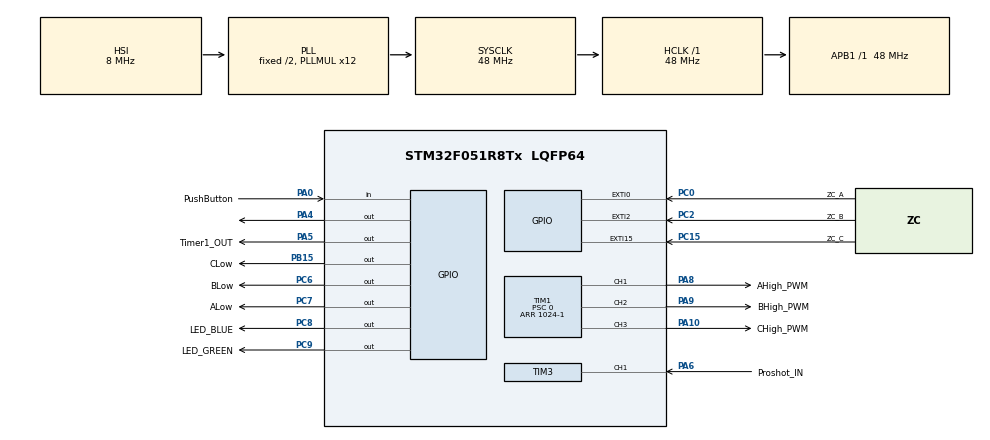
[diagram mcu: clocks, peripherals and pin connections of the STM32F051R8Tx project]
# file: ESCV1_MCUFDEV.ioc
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Dma.Request0=TIM3_CH1/TRIG
Dma.Request1=TIM1_CH2
Dma.Request2=TIM1_CH3/UP
Dma.Request3=TIM1_CH1
Dma.TIM1_CH1.3.Direction=DMA_MEMORY_TO_PERIPH
Dma.TIM1_CH1.3.Instance=DMA1_Channel2
Dma.TIM1_CH1.3.MemDataAlignment=DMA_MDATAALIGN_HALFWORD
Dma.TIM1_CH1.3.MemInc=DMA_MINC_ENABLE
Dma.TIM1_CH1.3.Mode=DMA_CIRCULAR
Dma.TIM1_CH1.3.PeriphDataAlignment=DMA_PDATAALIGN_HALFWORD
Dma.TIM1_CH1.3.PeriphInc=DMA_PINC_DISABLE
Dma.TIM1_CH1.3.Priority=DMA_PRIORITY_VERY_HIGH
Dma.TIM1_CH2.1.Direction=DMA_MEMORY_TO_PERIPH
Dma.TIM1_CH2.1.Instance=DMA1_Channel3
Dma.TIM1_CH2.1.MemDataAlignment=DMA_MDATAALIGN_HALFWORD
Dma.TIM1_CH2.1.MemInc=DMA_MINC_ENABLE
Dma.TIM1_CH2.1.Mode=DMA_CIRCULAR
Dma.TIM1_CH2.1.PeriphDataAlignment=DMA_PDATAALIGN_HALFWORD
Dma.TIM1_CH2.1.PeriphInc=DMA_PINC_DISABLE
Dma.TIM1_CH2.1.Priority=DMA_PRIORITY_VERY_HIGH
Dma.TIM1_CH3/UP.2.Direction=DMA_MEMORY_TO_PERIPH
Dma.TIM1_CH3/UP.2.Instance=DMA1_Channel5
Dma.TIM1_CH3/UP.2.MemDataAlignment=DMA_MDATAALIGN_HALFWORD
Dma.TIM1_CH3/UP.2.MemInc=DMA_MINC_ENABLE
Dma.TIM1_CH3/UP.2.Mode=DMA_CIRCULAR
Dma.TIM1_CH3/UP.2.PeriphDataAlignment=DMA_PDATAALIGN_HALFWORD
Dma.TIM1_CH3/UP.2.PeriphInc=DMA_PINC_DISABLE
Dma.TIM1_CH3/UP.2.Priority=DMA_PRIORITY_VERY_HIGH
Dma.TIM3_CH1/TRIG.0.Direction=DMA_PERIPH_TO_MEMORY
Dma.TIM3_CH1/TRIG.0.Instance=DMA1_Channel4
Dma.TIM3_CH1/TRIG.0.MemDataAlignment=DMA_MDATAALIGN_HALFWORD
Dma.TIM3_CH1/TRIG.0.MemInc=DMA_MINC_ENABLE
Dma.TIM3_CH1/TRIG.0.Mode=DMA_NORMAL
Dma.TIM3_CH1/TRIG.0.PeriphDataAlignment=DMA_PDATAALIGN_HALFWORD
Dma.TIM3_CH1/TRIG.0.PeriphInc=DMA_PINC_DISABLE
Dma.TIM3_CH1/TRIG.0.Priority=DMA_PRIORITY_VERY_HIGH
Mcu.Family=STM32F0
Mcu.Name=STM32F051R8Tx
Mcu.Package=LQFP64
NVIC.DMA1_Channel4_5_IRQn=true\:1\:0\:true\:false\:true\:true\:true
NVIC.EXTI0_1_IRQn=true\:0\:0\:false\:false\:true\:true\:true
NVIC.EXTI2_3_IRQn=true\:0\:0\:false\:false\:true\:true\:true
NVIC.EXTI4_15_IRQn=true\:0\:0\:false\:false\:true\:true\:true
NVIC.TIM2_IRQn=true\:0\:0\:true\:false\:true\:true\:true
PA0.GPIO_Label=PushButton
PA0.Signal=GPIO_Input
PA10.GPIO_Label=CHigh_PWM
PA10.GPIO_PuPd=GPIO_NOPULL
PA10.Signal=S_TIM1_CH3
PA13.Mode=Serial_Wire
PA13.Signal=SYS_SWDIO
PA14.Mode=Serial_Wire
PA14.Signal=SYS_SWCLK
PA4.Signal=GPIO_Output
PA5.GPIO_Label=Timer1_OUT
PA5.Signal=GPIO_Output
PA6.GPIO_Label=Proshot_IN
PA6.Signal=S_TIM3_CH1
PA8.GPIO_Label=AHigh_PWM
PA8.GPIO_PuPd=GPIO_NOPULL
PA8.Signal=S_TIM1_CH1
PA9.GPIO_Label=BHigh_PWM
PA9.GPIO_PuPd=GPIO_NOPULL
PA9.Signal=S_TIM1_CH2
PB15.GPIO_Label=CLow
PB15.GPIO_ModeDefaultOutputPP=GPIO_MODE_OUTPUT_PP
PB15.GPIO_PuPd=GPIO_PULLUP
PB15.GPIO_Speed=GPIO_SPEED_FREQ_HIGH
PB15.PinState=GPIO_PIN_SET
PB15.Signal=GPIO_Output
PC0.GPIO_Label=ZC_A
PC0.GPIO_ModeDefaultEXTI=GPIO_MODE_IT_FALLING
PC0.GPIO_PuPd=GPIO_PULLUP
PC0.Signal=GPXTI0
PC15-OSC32_OUT.GPIO_Label=ZC_C
PC15-OSC32_OUT.GPIO_ModeDefaultEXTI=GPIO_MODE_IT_FALLING
PC15-OSC32_OUT.GPIO_PuPd=GPIO_PULLUP
PC15-OSC32_OUT.Signal=GPXTI15
PC2.GPIO_Label=ZC_B
PC2.GPIO_ModeDefaultEXTI=GPIO_MODE_IT_FALLING
PC2.GPIO_PuPd=GPIO_PULLUP
PC2.Signal=GPXTI2
PC6.GPIO_Label=BLow
PC6.GPIO_ModeDefaultOutputPP=GPIO_MODE_OUTPUT_PP
PC6.GPIO_PuPd=GPIO_PULLUP
PC6.GPIO_Speed=GPIO_SPEED_FREQ_HIGH
PC6.PinState=GPIO_PIN_SET
PC6.Signal=GPIO_Output
PC7.GPIO_Label=ALow
PC7.GPIO_PuPd=GPIO_PULLUP
PC7.GPIO_Speed=GPIO_SPEED_FREQ_HIGH
PC7.PinState=GPIO_PIN_SET
PC7.Signal=GPIO_Output
PC8.GPIO_Label=LED_BLUE
PC8.Signal=GPIO_Output
PC9.GPIO_Label=LED_GREEN
PC9.GPIO_PuPd=GPIO_NOPULL
PC9.Signal=GPIO_Output
PF0-OSC_IN.Mode=HSE-External-Clock-Source
PF0-OSC_IN.Signal=RCC_OSC_IN
ProjectManager.HeapSize=0x200
ProjectManager.StackSize=0x400
ProjectManager.TargetToolchain=STM32CubeIDE
RCC.AHBFreq_Value=48000000
RCC.APB1Freq_Value=48000000
RCC.APB1TimFreq_Value=48000000
RCC.HCLKFreq_Value=48000000
RCC.PLLMUL=RCC_PLL_MUL12
RCC.SYSCLKFreq_VALUE=48000000
RCC.SYSCLKSource=RCC_SYSCLKSOURCE_PLLCLK
SH.S_TIM1_CH1.0=TIM1_CH1,PWM Generation1 CH1
SH.S_TIM1_CH2.0=TIM1_CH2,PWM Generation2 CH2
SH.S_TIM1_CH3.0=TIM1_CH3,PWM Generation3 CH3
SH.S_TIM3_CH1.0=TIM3_CH1,Input_Capture1_from_TI1
TIM1.Channel-PWM\ Generation1\ CH1=TIM_CHANNEL_1
TIM1.Channel-PWM\ Generation2\ CH2=TIM_CHANNEL_2
TIM1.Channel-PWM\ Generation3\ CH3=TIM_CHANNEL_3
TIM1.CounterMode=TIM_COUNTERMODE_UP
TIM1.Period=1024-1
TIM1.Prescaler=0
TIM1.Pulse-PWM\ Generation1\ CH1=200
TIM2.Period=100
TIM2.Prescaler=48000-1
TIM3.Channel-Input_Capture1_from_TI1=TIM_CHANNEL_1
TIM3.ICPolarity_CH1=TIM_INPUTCHANNELPOLARITY_BOTHEDGE
TIM6.Prescaler=0
VP_TIM2_VS_ClockSourceINT.Mode=Internal
VP_TIM6_VS_ClockSourceINT.Mode=Enable_Timer
board=custom

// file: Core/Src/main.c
/* USER CODE BEGIN Header */
/**
  ******************************************************************************
  * @file           : main.c
  * @brief          : Main program body
  ******************************************************************************
  * @attention
  *
  * Copyright (c) 2023 STMicroelectronics.
  * All rights reserved.
  *
  * This software is licensed under terms that can be found in the LICENSE file
  * in the root directory of this software component.
  * If no LICENSE file comes with this software, it is provided AS-IS.
  *
  ******************************************************************************
  */
/* USER CODE END Header */
#include "main.h"

TIM_HandleTypeDef htim1;
TIM_HandleTypeDef htim2;
TIM_HandleTypeDef htim3;
TIM_HandleTypeDef htim6;
DMA_HandleTypeDef hdma_tim1_ch2;
DMA_HandleTypeDef hdma_tim1_ch3_up;
DMA_HandleTypeDef hdma_tim1_ch1;
DMA_HandleTypeDef hdma_tim3_ch1_trig;

void SystemClock_Config(void);
static void MX_GPIO_Init(void);
static void MX_DMA_Init(void);
static void MX_TIM3_Init(void);
static void MX_TIM1_Init(void);
static void MX_TIM6_Init(void);
static void MX_TIM2_Init(void);

int main(void)
{

  /* MCU Configuration--------------------------------------------------------*/

  /* Reset of all peripherals, Initializes the Flash interface and the Systick. */
  HAL_Init();

  /* Configure the system clock */
  SystemClock_Config();

  /* USER CODE BEGIN SysInit */

  //For some reason swapping DMA_Init() with ADC_Init() allows DMA to request ADC to sample continuously.
  //Otherwise, in their original positions, ADC only performs ONE single conversion... or maybe DMA only grabs the data once.
  /* USER CODE END SysInit */

  /* Initialize all configured peripherals */
  MX_GPIO_Init();
  MX_DMA_Init();
  MX_TIM3_Init();
  MX_TIM1_Init();
  MX_TIM6_Init();
  MX_TIM2_Init();

  /* Infinite loop */
  /* USER CODE BEGIN WHILE */
  maincpp();			//Call main.cpp's main function.
  while (1)
  {
    /* USER CODE END WHILE */

  }
}

void SystemClock_Config(void)
{
  RCC_OscInitTypeDef RCC_OscInitStruct = {0};
  RCC_ClkInitTypeDef RCC_ClkInitStruct = {0};

  /** Initializes the RCC Oscillators according to the specified parameters
  * in the RCC_OscInitTypeDef structure.
  */
  RCC_OscInitStruct.OscillatorType = RCC_OSCILLATORTYPE_HSI;
  RCC_OscInitStruct.HSIState = RCC_HSI_ON;
  RCC_OscInitStruct.HSICalibrationValue = RCC_HSICALIBRATION_DEFAULT;
  RCC_OscInitStruct.PLL.PLLState = RCC_PLL_ON;
  RCC_OscInitStruct.PLL.PLLSource = RCC_PLLSOURCE_HSI;
  RCC_OscInitStruct.PLL.PLLMUL = RCC_PLL_MUL12;
  RCC_OscInitStruct.PLL.PREDIV = RCC_PREDIV_DIV1;
  if (HAL_RCC_OscConfig(&RCC_OscInitStruct) != HAL_OK)
  {
    Error_Handler();
  }
  /** Initializes the CPU, AHB and APB buses clocks
  */
  RCC_ClkInitStruct.ClockType = RCC_CLOCKTYPE_HCLK|RCC_CLOCKTYPE_SYSCLK
                              |RCC_CLOCKTYPE_PCLK1;
  RCC_ClkInitStruct.SYSCLKSource = RCC_SYSCLKSOURCE_PLLCLK;
  RCC_ClkInitStruct.AHBCLKDivider = RCC_SYSCLK_DIV1;
  RCC_ClkInitStruct.APB1CLKDivider = RCC_HCLK_DIV1;

  if (HAL_RCC_ClockConfig(&RCC_ClkInitStruct, FLASH_LATENCY_1) != HAL_OK)
  {
    Error_Handler();
  }
}

static void MX_TIM1_Init(void)
{

  TIM_MasterConfigTypeDef sMasterConfig = {0};
  TIM_OC_InitTypeDef sConfigOC = {0};
  TIM_BreakDeadTimeConfigTypeDef sBreakDeadTimeConfig = {0};

  htim1.Instance = TIM1;
  htim1.Init.Prescaler = 0;
  htim1.Init.CounterMode = TIM_COUNTERMODE_UP;
  htim1.Init.Period = 1024-1;
  htim1.Init.ClockDivision = TIM_CLOCKDIVISION_DIV1;
  htim1.Init.RepetitionCounter = 0;
  htim1.Init.AutoReloadPreload = TIM_AUTORELOAD_PRELOAD_DISABLE;
  if (HAL_TIM_PWM_Init(&htim1) != HAL_OK)
  {
    Error_Handler();
  }
  sMasterConfig.MasterOutputTrigger = TIM_TRGO_RESET;
  sMasterConfig.MasterSlaveMode = TIM_MASTERSLAVEMODE_DISABLE;
  if (HAL_TIMEx_MasterConfigSynchronization(&htim1, &sMasterConfig) != HAL_OK)
  {
    Error_Handler();
  }
  sConfigOC.OCMode = TIM_OCMODE_PWM1;
  sConfigOC.Pulse = 200;
  sConfigOC.OCPolarity = TIM_OCPOLARITY_HIGH;
  sConfigOC.OCNPolarity = TIM_OCNPOLARITY_HIGH;
  sConfigOC.OCFastMode = TIM_OCFAST_DISABLE;
  sConfigOC.OCIdleState = TIM_OCIDLESTATE_RESET;
  sConfigOC.OCNIdleState = TIM_OCNIDLESTATE_RESET;
  if (HAL_TIM_PWM_ConfigChannel(&htim1, &sConfigOC, TIM_CHANNEL_1) != HAL_OK)
  {
    Error_Handler();
  }
  sConfigOC.Pulse = 0;
  if (HAL_TIM_PWM_ConfigChannel(&htim1, &sConfigOC, TIM_CHANNEL_2) != HAL_OK)
  {
    Error_Handler();
  }
  if (HAL_TIM_PWM_ConfigChannel(&htim1, &sConfigOC, TIM_CHANNEL_3) != HAL_OK)
  {
    Error_Handler();
  }
  sBreakDeadTimeConfig.OffStateRunMode = TIM_OSSR_DISABLE;
  sBreakDeadTimeConfig.OffStateIDLEMode = TIM_OSSI_DISABLE;
  sBreakDeadTimeConfig.LockLevel = TIM_LOCKLEVEL_OFF;
  sBreakDeadTimeConfig.DeadTime = 0;
  sBreakDeadTimeConfig.BreakState = TIM_BREAK_DISABLE;
  sBreakDeadTimeConfig.BreakPolarity = TIM_BREAKPOLARITY_HIGH;
  sBreakDeadTimeConfig.AutomaticOutput = TIM_AUTOMATICOUTPUT_DISABLE;
  if (HAL_TIMEx_ConfigBreakDeadTime(&htim1, &sBreakDeadTimeConfig) != HAL_OK)
  {
    Error_Handler();
  }
  HAL_TIM_MspPostInit(&htim1);

}

static void MX_TIM2_Init(void)
{

  TIM_ClockConfigTypeDef sClockSourceConfig = {0};
  TIM_MasterConfigTypeDef sMasterConfig = {0};

  htim2.Instance = TIM2;
  htim2.Init.Prescaler = 48000-1;
  htim2.Init.CounterMode = TIM_COUNTERMODE_UP;
  htim2.Init.Period = 100;
  htim2.Init.ClockDivision = TIM_CLOCKDIVISION_DIV1;
  htim2.Init.AutoReloadPreload = TIM_AUTORELOAD_PRELOAD_DISABLE;
  if (HAL_TIM_Base_Init(&htim2) != HAL_OK)
  {
    Error_Handler();
  }
  sClockSourceConfig.ClockSource = TIM_CLOCKSOURCE_INTERNAL;
  if (HAL_TIM_ConfigClockSource(&htim2, &sClockSourceConfig) != HAL_OK)
  {
    Error_Handler();
  }
  sMasterConfig.MasterOutputTrigger = TIM_TRGO_RESET;
  sMasterConfig.MasterSlaveMode = TIM_MASTERSLAVEMODE_DISABLE;
  if (HAL_TIMEx_MasterConfigSynchronization(&htim2, &sMasterConfig) != HAL_OK)
  {
    Error_Handler();
  }

}

static void MX_TIM3_Init(void)
{

  TIM_MasterConfigTypeDef sMasterConfig = {0};
  TIM_IC_InitTypeDef sConfigIC = {0};

  htim3.Instance = TIM3;
  htim3.Init.Prescaler = 0;
  htim3.Init.CounterMode = TIM_COUNTERMODE_UP;
  htim3.Init.Period = 65535;
  htim3.Init.ClockDivision = TIM_CLOCKDIVISION_DIV1;
  htim3.Init.AutoReloadPreload = TIM_AUTORELOAD_PRELOAD_DISABLE;
  if (HAL_TIM_IC_Init(&htim3) != HAL_OK)
  {
    Error_Handler();
  }
  sMasterConfig.MasterOutputTrigger = TIM_TRGO_RESET;
  sMasterConfig.MasterSlaveMode = TIM_MASTERSLAVEMODE_DISABLE;
  if (HAL_TIMEx_MasterConfigSynchronization(&htim3, &sMasterConfig) != HAL_OK)
  {
    Error_Handler();
  }
  sConfigIC.ICPolarity = TIM_INPUTCHANNELPOLARITY_BOTHEDGE;
  sConfigIC.ICSelection = TIM_ICSELECTION_DIRECTTI;
  sConfigIC.ICPrescaler = TIM_ICPSC_DIV1;
  sConfigIC.ICFilter = 0;
  if (HAL_TIM_IC_ConfigChannel(&htim3, &sConfigIC, TIM_CHANNEL_1) != HAL_OK)
  {
    Error_Handler();
  }

}

static void MX_TIM6_Init(void)
{

  TIM_MasterConfigTypeDef sMasterConfig = {0};

  htim6.Instance = TIM6;
  htim6.Init.Prescaler = 0;
  htim6.Init.CounterMode = TIM_COUNTERMODE_UP;
  htim6.Init.Period = 65535;
  htim6.Init.AutoReloadPreload = TIM_AUTORELOAD_PRELOAD_DISABLE;
  if (HAL_TIM_Base_Init(&htim6) != HAL_OK)
  {
    Error_Handler();
  }
  sMasterConfig.MasterOutputTrigger = TIM_TRGO_RESET;
  sMasterConfig.MasterSlaveMode = TIM_MASTERSLAVEMODE_DISABLE;
  if (HAL_TIMEx_MasterConfigSynchronization(&htim6, &sMasterConfig) != HAL_OK)
  {
    Error_Handler();
  }

}

static void MX_DMA_Init(void)
{

  /* DMA controller clock enable */
  __HAL_RCC_DMA1_CLK_ENABLE();

  /* DMA interrupt init */
  /* DMA1_Channel4_5_IRQn interrupt configuration */
  HAL_NVIC_SetPriority(DMA1_Channel4_5_IRQn, 1, 0);
  HAL_NVIC_EnableIRQ(DMA1_Channel4_5_IRQn);

}

static void MX_GPIO_Init(void)
{
  GPIO_InitTypeDef GPIO_InitStruct = {0};

  /* GPIO Ports Clock Enable */
  __HAL_RCC_GPIOC_CLK_ENABLE();
  __HAL_RCC_GPIOF_CLK_ENABLE();
  __HAL_RCC_GPIOA_CLK_ENABLE();
  __HAL_RCC_GPIOB_CLK_ENABLE();

  /*Configure GPIO pin Output Level */
  HAL_GPIO_WritePin(GPIOA, GPIO_PIN_4|Timer1_OUT_Pin, GPIO_PIN_RESET);

  /*Configure GPIO pin Output Level */
  HAL_GPIO_WritePin(CLow_GPIO_Port, CLow_Pin, GPIO_PIN_SET);

  /*Configure GPIO pin Output Level */
  HAL_GPIO_WritePin(GPIOC, BLow_Pin|ALow_Pin, GPIO_PIN_SET);

  /*Configure GPIO pin Output Level */
  HAL_GPIO_WritePin(GPIOC, LED_BLUE_Pin|LED_GREEN_Pin, GPIO_PIN_RESET);

  /*Configure GPIO pins : ZC_C_Pin ZC_A_Pin ZC_B_Pin */
  GPIO_InitStruct.Pin = ZC_C_Pin|ZC_A_Pin|ZC_B_Pin;
  GPIO_InitStruct.Mode = GPIO_MODE_IT_FALLING;
  GPIO_InitStruct.Pull = GPIO_PULLUP;
  HAL_GPIO_Init(GPIOC, &GPIO_InitStruct);

  /*Configure GPIO pin : PushButton_Pin */
  GPIO_InitStruct.Pin = PushButton_Pin;
  GPIO_InitStruct.Mode = GPIO_MODE_INPUT;
  GPIO_InitStruct.Pull = GPIO_NOPULL;
  HAL_GPIO_Init(PushButton_GPIO_Port, &GPIO_InitStruct);

  /*Configure GPIO pins : PA4 Timer1_OUT_Pin */
  GPIO_InitStruct.Pin = GPIO_PIN_4|Timer1_OUT_Pin;
  GPIO_InitStruct.Mode = GPIO_MODE_OUTPUT_PP;
  GPIO_InitStruct.Pull = GPIO_NOPULL;
  GPIO_InitStruct.Speed = GPIO_SPEED_FREQ_LOW;
  HAL_GPIO_Init(GPIOA, &GPIO_InitStruct);

  /*Configure GPIO pin : CLow_Pin */
  GPIO_InitStruct.Pin = CLow_Pin;
  GPIO_InitStruct.Mode = GPIO_MODE_OUTPUT_PP;
  GPIO_InitStruct.Pull = GPIO_PULLUP;
  GPIO_InitStruct.Speed = GPIO_SPEED_FREQ_HIGH;
  HAL_GPIO_Init(CLow_GPIO_Port, &GPIO_InitStruct);

  /*Configure GPIO pins : BLow_Pin ALow_Pin */
  GPIO_InitStruct.Pin = BLow_Pin|ALow_Pin;
  GPIO_InitStruct.Mode = GPIO_MODE_OUTPUT_PP;
  GPIO_InitStruct.Pull = GPIO_PULLUP;
  GPIO_InitStruct.Speed = GPIO_SPEED_FREQ_HIGH;
  HAL_GPIO_Init(GPIOC, &GPIO_InitStruct);

  /*Configure GPIO pins : LED_BLUE_Pin LED_GREEN_Pin */
  GPIO_InitStruct.Pin = LED_BLUE_Pin|LED_GREEN_Pin;
  GPIO_InitStruct.Mode = GPIO_MODE_OUTPUT_PP;
  GPIO_InitStruct.Pull = GPIO_NOPULL;
  GPIO_InitStruct.Speed = GPIO_SPEED_FREQ_LOW;
  HAL_GPIO_Init(GPIOC, &GPIO_InitStruct);

  /* EXTI interrupt init*/
  HAL_NVIC_SetPriority(EXTI0_1_IRQn, 0, 0);
  HAL_NVIC_EnableIRQ(EXTI0_1_IRQn);

  HAL_NVIC_SetPriority(EXTI2_3_IRQn, 0, 0);
  HAL_NVIC_EnableIRQ(EXTI2_3_IRQn);

  HAL_NVIC_SetPriority(EXTI4_15_IRQn, 0, 0);
  HAL_NVIC_EnableIRQ(EXTI4_15_IRQn);

}

void Error_Handler(void)
{
  __disable_irq();
  while (1)
  {
  }
}
